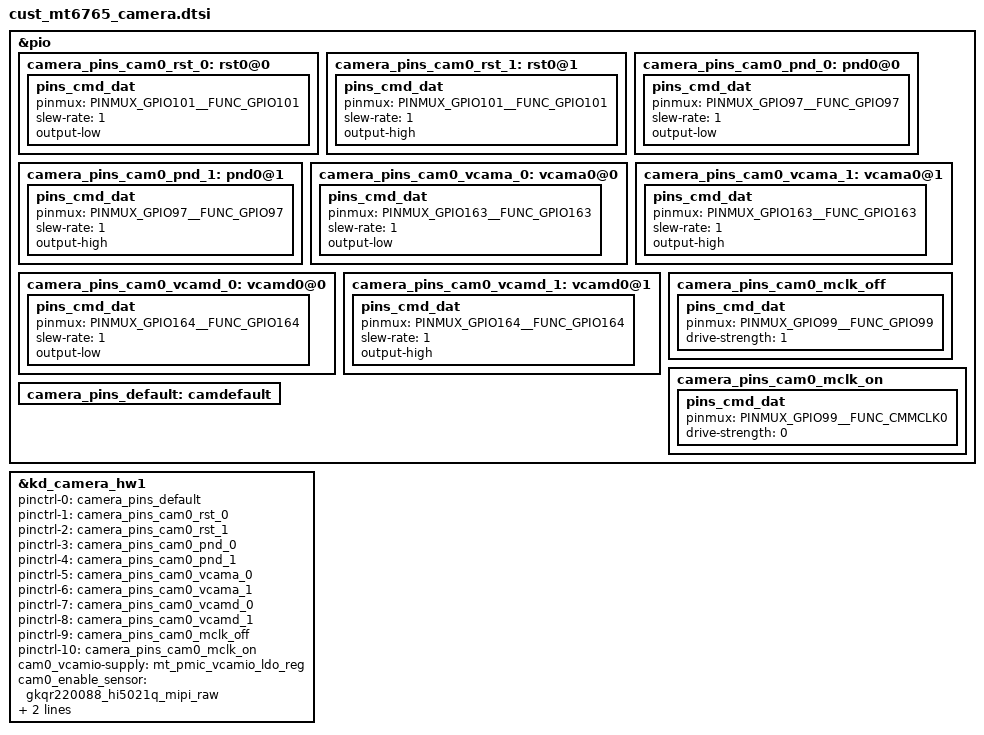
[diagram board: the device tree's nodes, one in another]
&pio {
	camera_pins_cam0_rst_0: rst0@0 {
		pins_cmd_dat {
			pinmux = <PINMUX_GPIO101__FUNC_GPIO101>;
			slew-rate = <1>;
			output-low;
		};
	};
	camera_pins_cam0_rst_1: rst0@1 {
		pins_cmd_dat {
			pinmux = <PINMUX_GPIO101__FUNC_GPIO101>;
			slew-rate = <1>;
			output-high;
		};
	};
	camera_pins_cam0_pnd_0: pnd0@0 {
		pins_cmd_dat {
			pinmux = <PINMUX_GPIO97__FUNC_GPIO97>;
			slew-rate = <1>;
			output-low;
		};
	};
	camera_pins_cam0_pnd_1: pnd0@1 {
		pins_cmd_dat {
			pinmux = <PINMUX_GPIO97__FUNC_GPIO97>;
			slew-rate = <1>;
			output-high;
		};
	};
	camera_pins_cam0_vcama_0: vcama0@0 {
		pins_cmd_dat {
			pinmux = <PINMUX_GPIO163__FUNC_GPIO163>;
			slew-rate = <1>;
			output-low;
		};
	};
	camera_pins_cam0_vcama_1: vcama0@1 {
		pins_cmd_dat {
			pinmux = <PINMUX_GPIO163__FUNC_GPIO163>;
			slew-rate = <1>;
			output-high;
		};
	};
	camera_pins_cam0_vcamd_0: vcamd0@0 {
		pins_cmd_dat {
			pinmux = <PINMUX_GPIO164__FUNC_GPIO164>;
			slew-rate = <1>;
			output-low;
		};
	};
	camera_pins_cam0_vcamd_1: vcamd0@1 {
		pins_cmd_dat {
			pinmux = <PINMUX_GPIO164__FUNC_GPIO164>;
			slew-rate = <1>;
			output-high;
		};
	};
	camera_pins_cam0_mclk_off: camera_pins_cam0_mclk_off {
		pins_cmd_dat {
			pinmux = <PINMUX_GPIO99__FUNC_GPIO99>;
			drive-strength = <1>;
		};
	};
	camera_pins_cam0_mclk_on: camera_pins_cam0_mclk_on {
		pins_cmd_dat {
			pinmux = <PINMUX_GPIO99__FUNC_CMMCLK0>;
			drive-strength = <0>;
		};
	};
	camera_pins_default: camdefault {
	};
};

&kd_camera_hw1 {
	pinctrl-names = "default",
		"cam0_rst0", "cam0_rst1",
		"cam0_pnd0", "cam0_pnd1",
		"cam0_vcama_off", "cam0_vcama_on",
		"cam0_vcamd_off", "cam0_vcamd_on",
		"cam0_mclk_off",
		"cam0_mclk_on";

	pinctrl-0 = <&camera_pins_default>;
	pinctrl-1 = <&camera_pins_cam0_rst_0>;
	pinctrl-2 = <&camera_pins_cam0_rst_1>;
	pinctrl-3 = <&camera_pins_cam0_pnd_0>;
	pinctrl-4 = <&camera_pins_cam0_pnd_1>;
	pinctrl-5 = <&camera_pins_cam0_vcama_0>;
	pinctrl-6 = <&camera_pins_cam0_vcama_1>;
	pinctrl-7 = <&camera_pins_cam0_vcamd_0>;
	pinctrl-8 = <&camera_pins_cam0_vcamd_1>;
	pinctrl-9 = <&camera_pins_cam0_mclk_off>;
	pinctrl-10 = <&camera_pins_cam0_mclk_on>;

	cam0_vcamio-supply = <&mt_pmic_vcamio_ldo_reg>;

	cam0_enable_sensor = "gkqr220088_hi5021q_mipi_raw";

	cam0_hw_cfg = "i2c 2 mclk clk rst gpio pnd gpio vcama gpio vcamd gpio vcamio pmic  none none";

	status = "okay";
};
